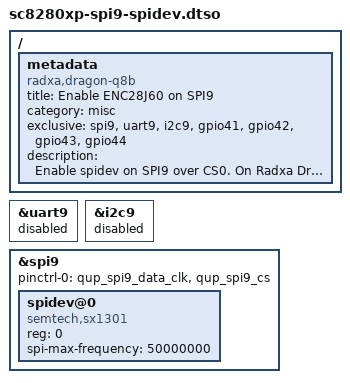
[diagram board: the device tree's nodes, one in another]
// SPDX-License-Identifier: BSD-3-Clause
/*
 * Copyright (c) 2026 Radxa Computer (Shenzhen) Co., Ltd.
 */

/dts-v1/;
/plugin/;

/ {
	metadata {
		title = "Enable ENC28J60 on SPI9";
		compatible = "radxa,dragon-q8b";
		category = "misc";
		exclusive = "spi9", "uart9", "i2c9", "gpio41", "gpio42", "gpio43", "gpio44";
		description = "Enable spidev on SPI9 over CS0.
On Radxa Dragon Q8B, this is pin 3(miso), 5(mosi), 27(sclk), 28(cs0).";
	};
};

&uart9 {
	status = "disabled";
};

&i2c9 {
	status = "disabled";
};

&spi9 {
	pinctrl-0 = <&qup_spi9_data_clk>, <&qup_spi9_cs>;
	pinctrl-names = "default";
	
	status = "okay";
	
	spidev@0 {
		compatible = "semtech,sx1301";
		status = "okay";
		reg = <0>;
		spi-max-frequency = <50000000>;
	};
};
